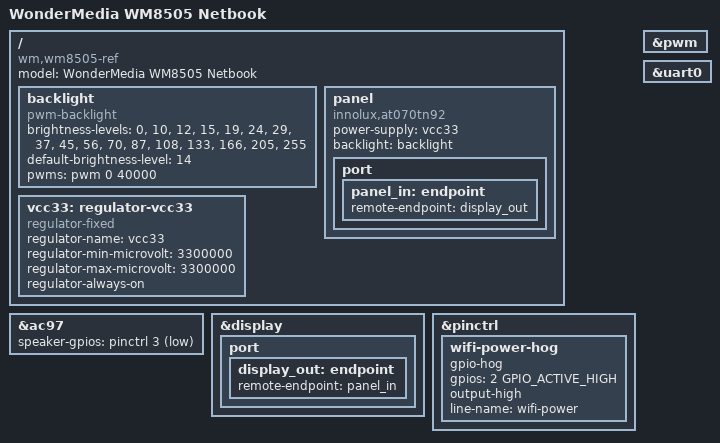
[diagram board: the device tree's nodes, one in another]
// SPDX-License-Identifier: GPL-2.0-or-later
/*
 * wm8505-ref.dts - Device tree file for WonderMedia WM8505 reference netbook
 *
 * Copyright (C) 2012 Tony Prisk <linux@prisktech.co.nz>
 * Copyright (C) 2026 Logan Russell <me@lrussell.net>
 */

/dts-v1/;

#include <dt-bindings/gpio/gpio.h>
#include "wm8505.dtsi"

/ {
	model = "WonderMedia WM8505 Netbook";
	compatible = "wm,wm8505-ref", "wm,wm8505";

	backlight: backlight {
		compatible = "pwm-backlight";
		brightness-levels = <0>, <10>, <12>, <15>, <19>, <24>, <29>,
				    <37>, <45>, <56>, <70>, <87>, <108>,
				    <133>, <166>, <205>, <255>;
		default-brightness-level = <14>;
		pwms = <&pwm 0 40000>;
	};

	panel {
		compatible = "innolux,at070tn92";
		power-supply = <&vcc33>;
		backlight = <&backlight>;

		port {
			panel_in: endpoint {
				remote-endpoint = <&display_out>;
			};
		};
	};

	vcc33: regulator-vcc33 {
		compatible = "regulator-fixed";
		regulator-name = "vcc33";
		regulator-min-microvolt = <3300000>;
		regulator-max-microvolt = <3300000>;
		regulator-always-on;
	};
};

&ac97 {
	speaker-gpios = <&pinctrl 3 GPIO_ACTIVE_LOW>;
	status = "okay";
};

&display {
	status = "okay";

	port {
		display_out: endpoint {
			remote-endpoint = <&panel_in>;
		};
	};
};

&pinctrl {
	wifi-power-hog {
		gpio-hog;
		gpios = <2 GPIO_ACTIVE_HIGH>;
		output-high;
		line-name = "wifi-power";
	};
};

&pwm {
	status = "okay";
};

&uart0 {
	status = "okay";
};
